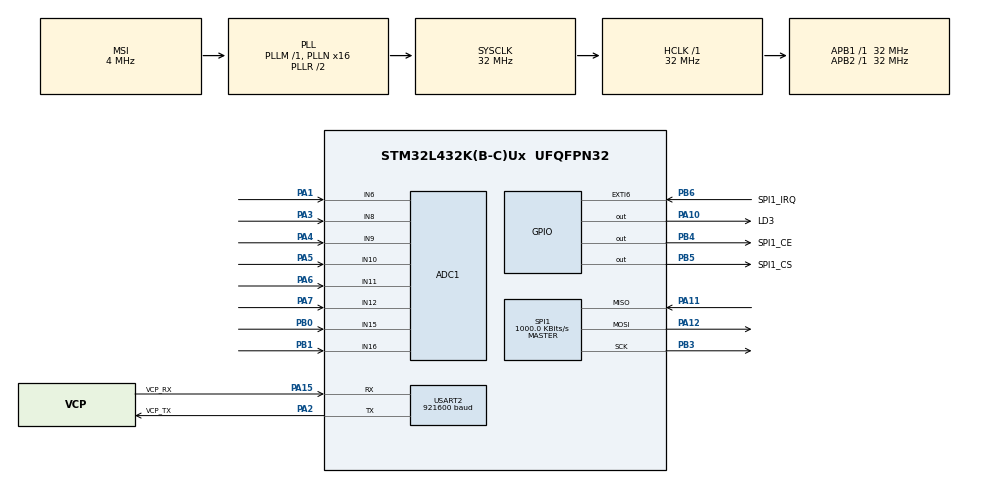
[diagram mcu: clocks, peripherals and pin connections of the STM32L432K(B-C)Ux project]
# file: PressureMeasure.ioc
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ADC1.Channel-1\#ChannelRegularConversion=ADC_CHANNEL_8
ADC1.Channel-2\#ChannelRegularConversion=ADC_CHANNEL_9
ADC1.Channel-3\#ChannelRegularConversion=ADC_CHANNEL_10
ADC1.Channel-4\#ChannelRegularConversion=ADC_CHANNEL_11
ADC1.Channel-5\#ChannelRegularConversion=ADC_CHANNEL_12
ADC1.Channel-6\#ChannelRegularConversion=ADC_CHANNEL_15
ADC1.Channel-7\#ChannelRegularConversion=ADC_CHANNEL_16
ADC1.Channel-8\#ChannelRegularConversion=ADC_CHANNEL_6
ADC1.ClockPrescaler=ADC_CLOCK_SYNC_PCLK_DIV1
ADC1.ContinuousConvMode=DISABLE
ADC1.EOCSelection=ADC_EOC_SEQ_CONV
ADC1.ExternalTrigConv=ADC_SOFTWARE_START
ADC1.NbrOfConversion=8
ADC1.NbrOfConversionFlag=1
ADC1.OffsetNumber-1\#ChannelRegularConversion=ADC_OFFSET_NONE
ADC1.OffsetNumber-2\#ChannelRegularConversion=ADC_OFFSET_NONE
ADC1.OffsetNumber-3\#ChannelRegularConversion=ADC_OFFSET_NONE
ADC1.OffsetNumber-4\#ChannelRegularConversion=ADC_OFFSET_NONE
ADC1.OffsetNumber-5\#ChannelRegularConversion=ADC_OFFSET_NONE
ADC1.OffsetNumber-6\#ChannelRegularConversion=ADC_OFFSET_NONE
ADC1.OffsetNumber-7\#ChannelRegularConversion=ADC_OFFSET_NONE
ADC1.OffsetNumber-8\#ChannelRegularConversion=ADC_OFFSET_NONE
ADC1.Rank-1\#ChannelRegularConversion=1
ADC1.Rank-2\#ChannelRegularConversion=2
ADC1.Rank-3\#ChannelRegularConversion=3
ADC1.Rank-4\#ChannelRegularConversion=4
ADC1.Rank-5\#ChannelRegularConversion=5
ADC1.Rank-6\#ChannelRegularConversion=6
ADC1.Rank-7\#ChannelRegularConversion=7
ADC1.Rank-8\#ChannelRegularConversion=8
ADC1.SamplingTime-1\#ChannelRegularConversion=ADC_SAMPLETIME_47CYCLES_5
ADC1.SamplingTime-2\#ChannelRegularConversion=ADC_SAMPLETIME_47CYCLES_5
ADC1.SamplingTime-3\#ChannelRegularConversion=ADC_SAMPLETIME_47CYCLES_5
ADC1.SamplingTime-4\#ChannelRegularConversion=ADC_SAMPLETIME_47CYCLES_5
ADC1.SamplingTime-5\#ChannelRegularConversion=ADC_SAMPLETIME_47CYCLES_5
ADC1.SamplingTime-6\#ChannelRegularConversion=ADC_SAMPLETIME_47CYCLES_5
ADC1.SamplingTime-7\#ChannelRegularConversion=ADC_SAMPLETIME_47CYCLES_5
ADC1.SamplingTime-8\#ChannelRegularConversion=ADC_SAMPLETIME_47CYCLES_5
ADC1.master=1
Dma.ADC1.0.Direction=DMA_PERIPH_TO_MEMORY
Dma.ADC1.0.Instance=DMA1_Channel1
Dma.ADC1.0.MemDataAlignment=DMA_MDATAALIGN_HALFWORD
Dma.ADC1.0.MemInc=DMA_MINC_ENABLE
Dma.ADC1.0.Mode=DMA_NORMAL
Dma.ADC1.0.PeriphDataAlignment=DMA_PDATAALIGN_HALFWORD
Dma.ADC1.0.PeriphInc=DMA_PINC_DISABLE
Dma.ADC1.0.Priority=DMA_PRIORITY_LOW
Dma.Request0=ADC1
Mcu.Family=STM32L4
Mcu.Name=STM32L432K(B-C)Ux
Mcu.Package=UFQFPN32
NVIC.ADC1_IRQn=true\:0\:0\:false\:false\:true\:true\:true\:true
NVIC.DMA1_Channel1_IRQn=true\:0\:0\:false\:false\:true\:false\:true\:true
NVIC.EXTI9_5_IRQn=true\:0\:0\:false\:false\:true\:true\:true\:true
NVIC.PriorityGroup=NVIC_PRIORITYGROUP_4
NVIC.TIM1_UP_TIM16_IRQn=true\:0\:0\:false\:false\:true\:true\:true\:true
PA0.GPIO_Label=MCO [High speed clock in]
PA0.Mode=HSE-External-Clock-Source-for-LittleOrca
PA0.Signal=RCC_CK_IN
PA1.Signal=ADCx_IN6
PA10.GPIO_Label=LD3
PA10.Signal=GPIO_Output
PA11.Mode=Full_Duplex_Master
PA11.Signal=SPI1_MISO
PA12.Mode=Full_Duplex_Master
PA12.Signal=SPI1_MOSI
PA13\ (JTMS-SWDIO).GPIO_Label=SWDIO
PA13\ (JTMS-SWDIO).Mode=Serial_Wire
PA13\ (JTMS-SWDIO).Signal=SYS_JTMS-SWDIO
PA14\ (JTCK-SWCLK).GPIO_Label=SWCLK
PA14\ (JTCK-SWCLK).Mode=Serial_Wire
PA14\ (JTCK-SWCLK).Signal=SYS_JTCK-SWCLK
PA15\ (JTDI).GPIO_Label=VCP_RX
PA15\ (JTDI).Mode=Asynchronous
PA15\ (JTDI).Signal=USART2_RX
PA2.GPIO_Label=VCP_TX
PA2.Mode=Asynchronous
PA2.Signal=USART2_TX
PA3.Signal=ADCx_IN8
PA4.Signal=ADCx_IN9
PA5.Signal=ADCx_IN10
PA6.Signal=ADCx_IN11
PA7.Signal=ADCx_IN12
PB0.Signal=ADCx_IN15
PB1.Signal=ADCx_IN16
PB3\ (JTDO-TRACESWO).Mode=Full_Duplex_Master
PB3\ (JTDO-TRACESWO).Signal=SPI1_SCK
PB4\ (NJTRST).GPIO_Label=SPI1_CE
PB4\ (NJTRST).Signal=GPIO_Output
PB5.GPIO_Label=SPI1_CS
PB5.Signal=GPIO_Output
PB6.GPIO_Label=SPI1_IRQ
PB6.GPIO_ModeDefaultEXTI=GPIO_MODE_IT_FALLING
PB6.Signal=GPXTI6
PC14-OSC32_IN\ (PC14).Mode=LSE-External-Oscillator
PC14-OSC32_IN\ (PC14).Signal=RCC_OSC32_IN
PC15-OSC32_OUT\ (PC15).Mode=LSE-External-Oscillator
PC15-OSC32_OUT\ (PC15).Signal=RCC_OSC32_OUT
ProjectManager.HeapSize=0x200
ProjectManager.StackSize=0x400
ProjectManager.TargetToolchain=STM32CubeIDE
RCC.ADCFreq_Value=32000000
RCC.AHBFreq_Value=32000000
RCC.APB1Freq_Value=32000000
RCC.APB1TimFreq_Value=32000000
RCC.APB2Freq_Value=32000000
RCC.APB2TimFreq_Value=32000000
RCC.CortexFreq_Value=32000000
RCC.HCLKFreq_Value=32000000
RCC.HSE_VALUE=8000000
RCC.HSI16_VALUE=16000000
RCC.HSI48_VALUE=48000000
RCC.HSI_VALUE=16000000
RCC.MSI_VALUE=4000000
RCC.PLLMUL=RCC_PLLMUL_4
RCC.PLLN=16
RCC.PLLSAI1N=16
RCC.SYSCLKFreq_VALUE=32000000
RCC.SYSCLKSource=RCC_SYSCLKSOURCE_PLLCLK
RCC.USBFreq_Value=32000000
RCC.VCOOutputFreq_Value=64000000
SH.ADCx_IN10.0=ADC1_IN10,IN10-Single-Ended
SH.ADCx_IN11.0=ADC1_IN11,IN11-Single-Ended
SH.ADCx_IN12.0=ADC1_IN12,IN12-Single-Ended
SH.ADCx_IN15.0=ADC1_IN15,IN15-Single-Ended
SH.ADCx_IN16.0=ADC1_IN16,IN16-Single-Ended
SH.ADCx_IN6.0=ADC1_IN6,IN6-Single-Ended
SH.ADCx_IN8.0=ADC1_IN8,IN8-Single-Ended
SH.ADCx_IN9.0=ADC1_IN9,IN9-Single-Ended
SPI1.BaudRatePrescaler=SPI_BAUDRATEPRESCALER_32
SPI1.CalculateBaudRate=1000.0 KBits/s
SPI1.DataSize=SPI_DATASIZE_8BIT
SPI1.Direction=SPI_DIRECTION_2LINES
SPI1.Mode=SPI_MODE_MASTER
SPI1.VirtualType=VM_MASTER
TIM16.Period=MEASURE_INTERVAL
TIM16.Prescaler=31
USART2.BaudRate=921600
USART2.VirtualMode-Asynchronous=VM_ASYNC
VP_TIM16_VS_ClockSourceINT.Mode=Enable_Timer
board=NUCLEO-L432KC

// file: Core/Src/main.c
/* USER CODE BEGIN Header */
/**
  ******************************************************************************
  * @file           : main.c
  * @brief          : Main program body
  ******************************************************************************
  * @attention
  *
  * Copyright (c) 2023 STMicroelectronics.
  * All rights reserved.
  *
  * This software is licensed under terms that can be found in the LICENSE file
  * in the root directory of this software component.
  * If no LICENSE file comes with this software, it is provided AS-IS.
  *
  ******************************************************************************
  */
/* USER CODE END Header */
#include "main.h"

/* USER CODE BEGIN Includes */
#include "app.h"
/* USER CODE END Includes */

/* USER CODE BEGIN PD */
//volatile uint8_t flag_tim;

/* USER CODE END PD */

ADC_HandleTypeDef hadc1;
DMA_HandleTypeDef hdma_adc1;

SPI_HandleTypeDef hspi1;

TIM_HandleTypeDef htim16;

UART_HandleTypeDef huart2;

void SystemClock_Config(void);
static void MX_GPIO_Init(void);
static void MX_DMA_Init(void);
static void MX_USART2_UART_Init(void);
static void MX_ADC1_Init(void);
static void MX_TIM16_Init(void);
static void MX_SPI1_Init(void);

int main(void)
{

  /* MCU Configuration--------------------------------------------------------*/

  /* Reset of all peripherals, Initializes the Flash interface and the Systick. */
  HAL_Init();

  /* Configure the system clock */
  SystemClock_Config();

  /* Initialize all configured peripherals */
  MX_GPIO_Init();
  MX_DMA_Init();
  MX_USART2_UART_Init();
  MX_ADC1_Init();
  MX_TIM16_Init();
  MX_SPI1_Init();

  /* Infinite loop */
  /* USER CODE BEGIN WHILE */
  appTransmitter();
  while (1)
  {
    /* USER CODE END WHILE */

  }
}

void SystemClock_Config(void)
{
  RCC_OscInitTypeDef RCC_OscInitStruct = {0};
  RCC_ClkInitTypeDef RCC_ClkInitStruct = {0};

  /** Configure the main internal regulator output voltage
  */
  if (HAL_PWREx_ControlVoltageScaling(PWR_REGULATOR_VOLTAGE_SCALE1) != HAL_OK)
  {
    Error_Handler();
  }

  /** Configure LSE Drive Capability
  */
  HAL_PWR_EnableBkUpAccess();
  __HAL_RCC_LSEDRIVE_CONFIG(RCC_LSEDRIVE_LOW);

  /** Initializes the RCC Oscillators according to the specified parameters
  * in the RCC_OscInitTypeDef structure.
  */
  RCC_OscInitStruct.OscillatorType = RCC_OSCILLATORTYPE_LSE|RCC_OSCILLATORTYPE_MSI;
  RCC_OscInitStruct.LSEState = RCC_LSE_ON;
  RCC_OscInitStruct.MSIState = RCC_MSI_ON;
  RCC_OscInitStruct.MSICalibrationValue = 0;
  RCC_OscInitStruct.MSIClockRange = RCC_MSIRANGE_6;
  RCC_OscInitStruct.PLL.PLLState = RCC_PLL_ON;
  RCC_OscInitStruct.PLL.PLLSource = RCC_PLLSOURCE_MSI;
  RCC_OscInitStruct.PLL.PLLM = 1;
  RCC_OscInitStruct.PLL.PLLN = 16;
  RCC_OscInitStruct.PLL.PLLP = RCC_PLLP_DIV7;
  RCC_OscInitStruct.PLL.PLLQ = RCC_PLLQ_DIV2;
  RCC_OscInitStruct.PLL.PLLR = RCC_PLLR_DIV2;
  if (HAL_RCC_OscConfig(&RCC_OscInitStruct) != HAL_OK)
  {
    Error_Handler();
  }

  /** Initializes the CPU, AHB and APB buses clocks
  */
  RCC_ClkInitStruct.ClockType = RCC_CLOCKTYPE_HCLK|RCC_CLOCKTYPE_SYSCLK
                              |RCC_CLOCKTYPE_PCLK1|RCC_CLOCKTYPE_PCLK2;
  RCC_ClkInitStruct.SYSCLKSource = RCC_SYSCLKSOURCE_PLLCLK;
  RCC_ClkInitStruct.AHBCLKDivider = RCC_SYSCLK_DIV1;
  RCC_ClkInitStruct.APB1CLKDivider = RCC_HCLK_DIV1;
  RCC_ClkInitStruct.APB2CLKDivider = RCC_HCLK_DIV1;

  if (HAL_RCC_ClockConfig(&RCC_ClkInitStruct, FLASH_LATENCY_1) != HAL_OK)
  {
    Error_Handler();
  }

  /** Enable MSI Auto calibration
  */
  HAL_RCCEx_EnableMSIPLLMode();
}

static void MX_ADC1_Init(void)
{

  ADC_ChannelConfTypeDef sConfig = {0};

  /** Common config
  */
  hadc1.Instance = ADC1;
  hadc1.Init.ClockPrescaler = ADC_CLOCK_SYNC_PCLK_DIV1;
  hadc1.Init.Resolution = ADC_RESOLUTION_12B;
  hadc1.Init.DataAlign = ADC_DATAALIGN_RIGHT;
  hadc1.Init.ScanConvMode = ADC_SCAN_ENABLE;
  hadc1.Init.EOCSelection = ADC_EOC_SEQ_CONV;
  hadc1.Init.LowPowerAutoWait = DISABLE;
  hadc1.Init.ContinuousConvMode = DISABLE;
  hadc1.Init.NbrOfConversion = 8;
  hadc1.Init.DiscontinuousConvMode = DISABLE;
  hadc1.Init.ExternalTrigConv = ADC_SOFTWARE_START;
  hadc1.Init.ExternalTrigConvEdge = ADC_EXTERNALTRIGCONVEDGE_NONE;
  hadc1.Init.DMAContinuousRequests = DISABLE;
  hadc1.Init.Overrun = ADC_OVR_DATA_PRESERVED;
  hadc1.Init.OversamplingMode = DISABLE;
  if (HAL_ADC_Init(&hadc1) != HAL_OK)
  {
    Error_Handler();
  }

  /** Configure Regular Channel
  */
  sConfig.Channel = ADC_CHANNEL_8;
  sConfig.Rank = ADC_REGULAR_RANK_1;
  sConfig.SamplingTime = ADC_SAMPLETIME_47CYCLES_5;
  sConfig.SingleDiff = ADC_SINGLE_ENDED;
  sConfig.OffsetNumber = ADC_OFFSET_NONE;
  sConfig.Offset = 0;
  if (HAL_ADC_ConfigChannel(&hadc1, &sConfig) != HAL_OK)
  {
    Error_Handler();
  }

  /** Configure Regular Channel
  */
  sConfig.Channel = ADC_CHANNEL_9;
  sConfig.Rank = ADC_REGULAR_RANK_2;
  if (HAL_ADC_ConfigChannel(&hadc1, &sConfig) != HAL_OK)
  {
    Error_Handler();
  }

  /** Configure Regular Channel
  */
  sConfig.Channel = ADC_CHANNEL_10;
  sConfig.Rank = ADC_REGULAR_RANK_3;
  if (HAL_ADC_ConfigChannel(&hadc1, &sConfig) != HAL_OK)
  {
    Error_Handler();
  }

  /** Configure Regular Channel
  */
  sConfig.Channel = ADC_CHANNEL_11;
  sConfig.Rank = ADC_REGULAR_RANK_4;
  if (HAL_ADC_ConfigChannel(&hadc1, &sConfig) != HAL_OK)
  {
    Error_Handler();
  }

  /** Configure Regular Channel
  */
  sConfig.Channel = ADC_CHANNEL_12;
  sConfig.Rank = ADC_REGULAR_RANK_5;
  if (HAL_ADC_ConfigChannel(&hadc1, &sConfig) != HAL_OK)
  {
    Error_Handler();
  }

  /** Configure Regular Channel
  */
  sConfig.Channel = ADC_CHANNEL_15;
  sConfig.Rank = ADC_REGULAR_RANK_6;
  if (HAL_ADC_ConfigChannel(&hadc1, &sConfig) != HAL_OK)
  {
    Error_Handler();
  }

  /** Configure Regular Channel
  */
  sConfig.Channel = ADC_CHANNEL_16;
  sConfig.Rank = ADC_REGULAR_RANK_7;
  if (HAL_ADC_ConfigChannel(&hadc1, &sConfig) != HAL_OK)
  {
    Error_Handler();
  }

  /** Configure Regular Channel
  */
  sConfig.Channel = ADC_CHANNEL_6;
  sConfig.Rank = ADC_REGULAR_RANK_8;
  if (HAL_ADC_ConfigChannel(&hadc1, &sConfig) != HAL_OK)
  {
    Error_Handler();
  }

}

static void MX_SPI1_Init(void)
{

  /* SPI1 parameter configuration*/
  hspi1.Instance = SPI1;
  hspi1.Init.Mode = SPI_MODE_MASTER;
  hspi1.Init.Direction = SPI_DIRECTION_2LINES;
  hspi1.Init.DataSize = SPI_DATASIZE_8BIT;
  hspi1.Init.CLKPolarity = SPI_POLARITY_LOW;
  hspi1.Init.CLKPhase = SPI_PHASE_1EDGE;
  hspi1.Init.NSS = SPI_NSS_SOFT;
  hspi1.Init.BaudRatePrescaler = SPI_BAUDRATEPRESCALER_32;
  hspi1.Init.FirstBit = SPI_FIRSTBIT_MSB;
  hspi1.Init.TIMode = SPI_TIMODE_DISABLE;
  hspi1.Init.CRCCalculation = SPI_CRCCALCULATION_DISABLE;
  hspi1.Init.CRCPolynomial = 7;
  hspi1.Init.CRCLength = SPI_CRC_LENGTH_DATASIZE;
  hspi1.Init.NSSPMode = SPI_NSS_PULSE_ENABLE;
  if (HAL_SPI_Init(&hspi1) != HAL_OK)
  {
    Error_Handler();
  }

}

static void MX_TIM16_Init(void)
{

  htim16.Instance = TIM16;
  htim16.Init.Prescaler = 31;
  htim16.Init.CounterMode = TIM_COUNTERMODE_UP;
  htim16.Init.Period = MEASURE_INTERVAL;
  htim16.Init.ClockDivision = TIM_CLOCKDIVISION_DIV1;
  htim16.Init.RepetitionCounter = 0;
  htim16.Init.AutoReloadPreload = TIM_AUTORELOAD_PRELOAD_DISABLE;
  if (HAL_TIM_Base_Init(&htim16) != HAL_OK)
  {
    Error_Handler();
  }

}

static void MX_USART2_UART_Init(void)
{

  huart2.Instance = USART2;
  huart2.Init.BaudRate = 921600;
  huart2.Init.WordLength = UART_WORDLENGTH_8B;
  huart2.Init.StopBits = UART_STOPBITS_1;
  huart2.Init.Parity = UART_PARITY_NONE;
  huart2.Init.Mode = UART_MODE_TX_RX;
  huart2.Init.HwFlowCtl = UART_HWCONTROL_NONE;
  huart2.Init.OverSampling = UART_OVERSAMPLING_16;
  huart2.Init.OneBitSampling = UART_ONE_BIT_SAMPLE_DISABLE;
  huart2.AdvancedInit.AdvFeatureInit = UART_ADVFEATURE_NO_INIT;
  if (HAL_UART_Init(&huart2) != HAL_OK)
  {
    Error_Handler();
  }

}

static void MX_DMA_Init(void)
{

  /* DMA controller clock enable */
  __HAL_RCC_DMA1_CLK_ENABLE();

  /* DMA interrupt init */
  /* DMA1_Channel1_IRQn interrupt configuration */
  HAL_NVIC_SetPriority(DMA1_Channel1_IRQn, 0, 0);
  HAL_NVIC_EnableIRQ(DMA1_Channel1_IRQn);

}

static void MX_GPIO_Init(void)
{
  GPIO_InitTypeDef GPIO_InitStruct = {0};

  /* GPIO Ports Clock Enable */
  __HAL_RCC_GPIOC_CLK_ENABLE();
  __HAL_RCC_GPIOA_CLK_ENABLE();
  __HAL_RCC_GPIOB_CLK_ENABLE();

  /*Configure GPIO pin Output Level */
  HAL_GPIO_WritePin(LD3_GPIO_Port, LD3_Pin, GPIO_PIN_RESET);

  /*Configure GPIO pin Output Level */
  HAL_GPIO_WritePin(GPIOB, SPI1_CE_Pin|SPI1_CS_Pin, GPIO_PIN_RESET);

  /*Configure GPIO pin : LD3_Pin */
  GPIO_InitStruct.Pin = LD3_Pin;
  GPIO_InitStruct.Mode = GPIO_MODE_OUTPUT_PP;
  GPIO_InitStruct.Pull = GPIO_NOPULL;
  GPIO_InitStruct.Speed = GPIO_SPEED_FREQ_LOW;
  HAL_GPIO_Init(LD3_GPIO_Port, &GPIO_InitStruct);

  /*Configure GPIO pins : SPI1_CE_Pin SPI1_CS_Pin */
  GPIO_InitStruct.Pin = SPI1_CE_Pin|SPI1_CS_Pin;
  GPIO_InitStruct.Mode = GPIO_MODE_OUTPUT_PP;
  GPIO_InitStruct.Pull = GPIO_NOPULL;
  GPIO_InitStruct.Speed = GPIO_SPEED_FREQ_LOW;
  HAL_GPIO_Init(GPIOB, &GPIO_InitStruct);

  /*Configure GPIO pin : SPI1_IRQ_Pin */
  GPIO_InitStruct.Pin = SPI1_IRQ_Pin;
  GPIO_InitStruct.Mode = GPIO_MODE_IT_FALLING;
  GPIO_InitStruct.Pull = GPIO_NOPULL;
  HAL_GPIO_Init(SPI1_IRQ_GPIO_Port, &GPIO_InitStruct);

  /* EXTI interrupt init*/
  HAL_NVIC_SetPriority(EXTI9_5_IRQn, 0, 0);
  HAL_NVIC_EnableIRQ(EXTI9_5_IRQn);

}

void Error_Handler(void)
{
  __disable_irq();
  while (1)
  {
  }
}
